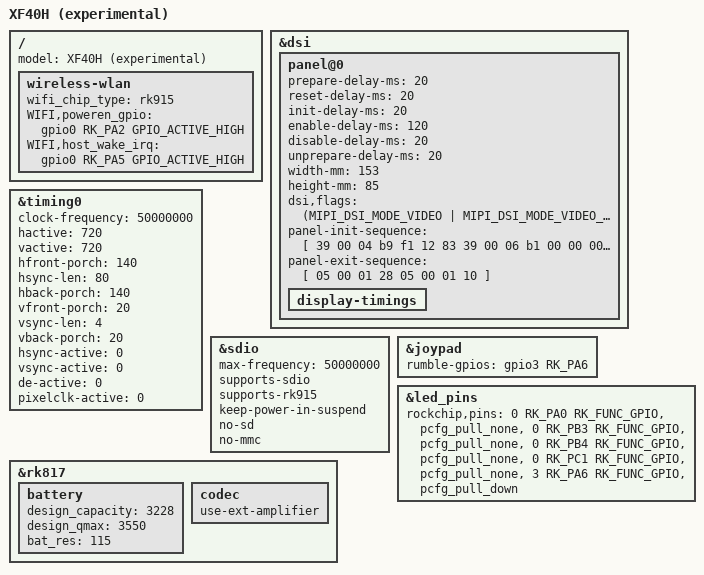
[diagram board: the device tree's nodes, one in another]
// SPDX-License-Identifier: (GPL-2.0+ OR MIT)
/*
 * EXPERIMENTAL - not tested on hardware by andr36oid. Keep a copy of the
 * files you replace so you can go back.
 *
 * XF40H (eMMC model): EE clone K36 wiring, 720x720 panel (the R36 Ultra
 * panel), RK915 SDIO Wi-Fi, rumble motor on GPIO3_A6, speaker through an
 * external amplifier, 3228 mAh.
 * Values from the stock DTB dumped from the console.
 */

/dts-v1/;
#include "rk3326-r36s-clone-ee-k36.dtsi"

/ {
	model = "XF40H (experimental)";
};

&dsi {
	panel@0 {
		prepare-delay-ms = <20>;
		reset-delay-ms = <20>;
		init-delay-ms = <20>;
		enable-delay-ms = <120>;
		disable-delay-ms = <20>;
		unprepare-delay-ms = <20>;
		width-mm = <153>;
		height-mm = <85>;
		dsi,flags = <(MIPI_DSI_MODE_VIDEO |
		      MIPI_DSI_MODE_VIDEO_BURST |
		      MIPI_DSI_MODE_EOT_PACKET |
		      MIPI_DSI_MODE_LPM)>;
		panel-init-sequence = [
			39 00 04 b9 f1 12 83
			39 00 06 b1 00 00 00 da 80
			39 00 04 b2 3c 12 30
			39 00 0b b3 10 10 28 28 03 ff 00 00 00 00
			15 00 02 b4 80
			39 00 03 b5 0a 0a
			39 00 03 b6 97 97
			39 00 05 b8 26 22 f0 13
			39 00 1c ba 33 81 05 f9 0e 0e 20 00 00 00 00 00 00 00 44 25 00 90 0a 00 00 01 4f 01 00 00 37
			15 00 02 bc 47
			39 00 04 bf 02 11 00
			39 00 0a c0 73 73 50 50 00 00 12 70 00
			39 00 0d c1 25 00 32 32 77 e4 ff ff cc cc 77 77
			39 00 07 c6 82 00 bf ff 00 ff
			39 00 07 c7 b8 00 0a 00 00 00
			39 00 05 c8 10 40 1e 02
			15 00 02 cc 0b
			39 00 23 e0 00 0b 10 2c 3d 3f 42 3a 07 0d 0f 13 15 13 14 0f 16 00 0b 10 2c 3d 3f 42 3a 07 0d 0f 13 15 13 14 0f 16
			39 00 0f e3 07 07 0b 0b 0b 0b 00 00 00 00 ff 00 c0 10
			39 00 40 e9 c8 10 0a 00 00 80 81 12 31 23 4f 86 a0 00 47 08 00 00 0c 00 00 00 00 00 0c 00 00 00 98 02 8b af 46 02 88 88 88 88 88 98 13 8b af 57 13 88 88 88 88 88 00 00 00 00 00 00 00 00 00 00 00 00 00
			39 00 3e ea 97 0c 09 09 09 78 00 00 00 00 00 00 9f 31 8b a8 31 75 88 88 88 88 88 9f 20 8b a8 20 64 88 88 88 88 88 23 00 00 02 71 00 00 00 00 00 00 00 00 00 00 00 00 00 00 00 40 80 81 00 00 00 00
			39 00 04 ef ff ff 01
			05 fa 01 11
			05 32 01 29
		];
		panel-exit-sequence = [
			05 00 01 28
			05 00 01 10
		];
		display-timings {
			/* one mode only: the R36S alternates below do not fit this panel */
			/delete-node/ timing1;
			/delete-node/ timing2;
		};
	};
};

&timing0 {
	clock-frequency = <50000000>;
	hactive = <720>;
	vactive = <720>;
	hfront-porch = <140>;
	hsync-len = <80>;
	hback-porch = <140>;
	vfront-porch = <20>;
	vsync-len = <4>;
	vback-porch = <20>;
	hsync-active = <0>;
	vsync-active = <0>;
	de-active = <0>;
	pixelclk-active = <0>;
};

/*
 * RK915 SDIO Wi-Fi instead of a second card slot. Power enable GPIO0_A2
 * (active high), out-of-band interrupt GPIO0_A5 (the R36 Ultra uses
 * GPIO0_A1), as in the stock DTB. Needs the RK915 driver (night/rk915),
 * which reads supports-rk915 and wifi_chip_type "rk915"; kernels without
 * it ignore both. (Stock sets "supports-rk912"; the 4.19 driver uses
 * "supports-rk915".)
 */
/ {
	wireless-wlan {
		wifi_chip_type = "rk915";
		WIFI,poweren_gpio = <&gpio0 RK_PA2 GPIO_ACTIVE_HIGH>;
		WIFI,host_wake_irq = <&gpio0 RK_PA5 GPIO_ACTIVE_HIGH>;
	};
};

&sdio {
	/delete-property/ supports-sd;
	/delete-property/ cd-gpios;
	/delete-property/ card-detect-delay;
	/delete-property/ cap-mmc-highspeed;
	/delete-property/ sd-uhs-sdr12;
	/delete-property/ sd-uhs-sdr25;
	/delete-property/ sd-uhs-sdr50;
	/delete-property/ sd-uhs-sdr104;
	/delete-property/ vmmc-supply;
	/delete-property/ vqmmc-supply;
	max-frequency = <50000000>;
	supports-sdio;
	supports-rk915;
	keep-power-in-suspend;
	no-sd;
	no-mmc;
};

/*
 * rumble motor ("moto-gpio" in the stock DTB, active high). The joypad
 * drives it so games see it as gamepad rumble; led_pins keeps the pin
 * pulled down until the joypad driver takes it.
 */
&joypad {
	rumble-gpios = <&gpio3 RK_PA6 GPIO_ACTIVE_HIGH>;
};

&led_pins {
	rockchip,pins =
		<0 RK_PA0 RK_FUNC_GPIO &pcfg_pull_none>,
		<0 RK_PB3 RK_FUNC_GPIO &pcfg_pull_none>,
		<0 RK_PB4 RK_FUNC_GPIO &pcfg_pull_none>,
		<0 RK_PC1 RK_FUNC_GPIO &pcfg_pull_none>,
		<3 RK_PA6 RK_FUNC_GPIO &pcfg_pull_down>;
};

&rk817 {
	battery {
		design_capacity = <3228>;
		design_qmax = <3550>;
		bat_res = <115>;
	};
};

/* the speaker runs through an external amplifier (stock "use-ext-amplifier") */
&rk817 {
	codec {
		use-ext-amplifier;
	};
};
